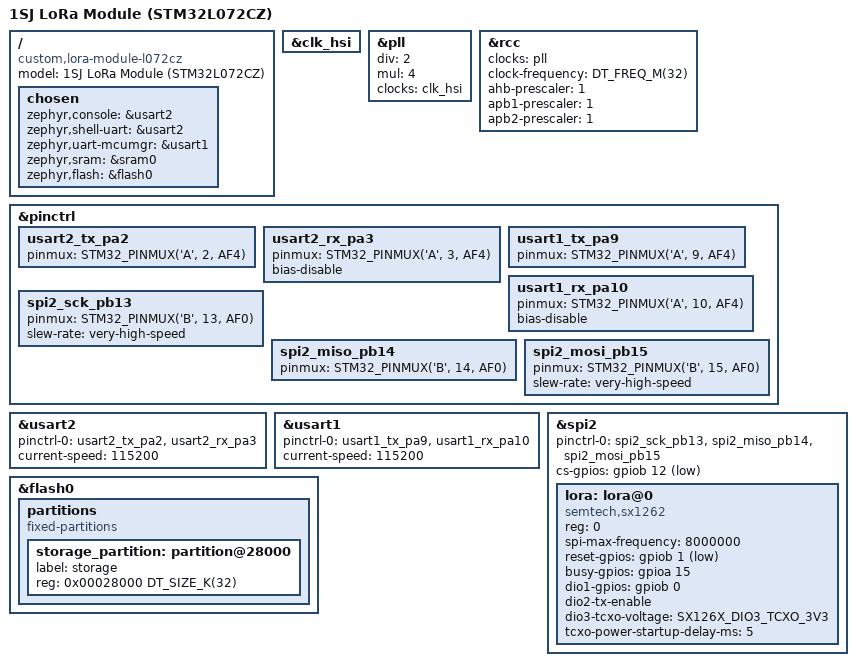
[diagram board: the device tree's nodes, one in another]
/*
 * Copyright (c) 2024
 * SPDX-License-Identifier: Apache-2.0
 *
 * 1SJ LoRa Module — STM32L072CZ + SX1262
 * Shell UART: USART2 on PA2 (TX) / PA3 (RX), AF4
 */

/dts-v1/;
#include <st/l0/stm32l072Xz.dtsi>
#include <zephyr/dt-bindings/pinctrl/stm32-pinctrl.h>
#include <zephyr/dt-bindings/input/input-event-codes.h>
#include <zephyr/dt-bindings/lora/sx126x.h>

/ {
	model = "1SJ LoRa Module (STM32L072CZ)";
	compatible = "custom,lora-module-l072cz";

	chosen {
		zephyr,console    = &usart2;
		zephyr,shell-uart = &usart2;
		zephyr,uart-mcumgr = &usart1;   /* SMP coprocessor interface */
		zephyr,sram       = &sram0;
		zephyr,flash      = &flash0;
	};

};

/* ── Clocks ─────────────────────────────────────────────────────── */

&clk_hsi {
	/* 16 MHz internal RC → PLL → 32 MHz system clock */
	status = "okay";
};

&pll {
	div = <2>;
	mul = <4>;
	clocks = <&clk_hsi>;
	status = "okay";
};

&rcc {
	clocks = <&pll>;
	clock-frequency = <DT_FREQ_M(32)>;
	ahb-prescaler = <1>;
	apb1-prescaler = <1>;
	apb2-prescaler = <1>;
};

/* ── Pinctrl (inline — no external pinctrl DTSI required) ───────── */

&pinctrl {
	usart2_tx_pa2: usart2_tx_pa2 {
		pinmux = <STM32_PINMUX('A', 2, AF4)>;
	};
	usart2_rx_pa3: usart2_rx_pa3 {
		pinmux = <STM32_PINMUX('A', 3, AF4)>;
		bias-disable;
	};

	/* USART1: PA9=TX, PA10=RX (AF4 on STM32L072) — SMP coprocessor interface */
	usart1_tx_pa9: usart1_tx_pa9 {
		pinmux = <STM32_PINMUX('A', 9, AF4)>;
	};
	usart1_rx_pa10: usart1_rx_pa10 {
		pinmux = <STM32_PINMUX('A', 10, AF4)>;
		bias-disable;
	};

	/* SPI2: PB13=SCK, PB14=MISO, PB15=MOSI  (AF0 on STM32L072) */
	spi2_sck_pb13: spi2_sck_pb13 {
		pinmux = <STM32_PINMUX('B', 13, AF0)>;
		slew-rate = "very-high-speed";
	};
	spi2_miso_pb14: spi2_miso_pb14 {
		pinmux = <STM32_PINMUX('B', 14, AF0)>;
	};
	spi2_mosi_pb15: spi2_mosi_pb15 {
		pinmux = <STM32_PINMUX('B', 15, AF0)>;
		slew-rate = "very-high-speed";
	};
};

/* ── USART2: shell / console on PA2/PA3 ─────────────────────────── */

&usart2 {
	pinctrl-0 = <&usart2_tx_pa2 &usart2_rx_pa3>;
	pinctrl-names = "default";
	current-speed = <115200>;
	status = "okay";
};

/* ── USART1: SMP coprocessor interface on PA9/PA10 ──────────────── */

&usart1 {
	pinctrl-0 = <&usart1_tx_pa9 &usart1_rx_pa10>;
	pinctrl-names = "default";
	current-speed = <115200>;
	status = "okay";
};

/* ── SPI2: SX1262 LoRa transceiver ──────────────────────────────── */
/*
 * PB12 = NSS (software CS, active-low)
 * PB13 = SCK, PB14 = MISO, PB15 = MOSI
 * All internal — not exposed on module header.
 */

&spi2 {
	pinctrl-0 = <&spi2_sck_pb13 &spi2_miso_pb14 &spi2_mosi_pb15>;
	pinctrl-names = "default";
	cs-gpios = <&gpiob 12 GPIO_ACTIVE_LOW>;
	status = "okay";

	lora: lora@0 {
		compatible = "semtech,sx1262";
		reg = <0>;
		spi-max-frequency = <8000000>;
		reset-gpios = <&gpiob 1 GPIO_ACTIVE_LOW>;
		busy-gpios  = <&gpioa 15 GPIO_ACTIVE_HIGH>;
		dio1-gpios  = <&gpiob 0 GPIO_ACTIVE_HIGH>;
		dio2-tx-enable;
		dio3-tcxo-voltage = <SX126X_DIO3_TCXO_3V3>;
		tcxo-power-startup-delay-ms = <5>;
	};
};

/* ── Flash partitions ────────────────────────────────────────────── */

&flash0 {
	partitions {
		compatible = "fixed-partitions";
		#address-cells = <1>;
		#size-cells = <1>;

		/* 32 KiB NVS storage at end of 192 KiB flash */
		storage_partition: partition@28000 {
			label = "storage";
			reg = <0x00028000 DT_SIZE_K(32)>;
		};
	};
};
